# ISP_HIST register map
Vendor: Texas Instruments
Peripheral module from a debugger description file (folder omap36xx).
Registers are 32-bit, read-write, reset 0x0 unless marked. A register's access mark holds for its fields unless they carry their own. Offsets are as the file gives them; lines under a group give offsets from that group; [hi:lo] are bit positions; {n}, {i} and the like mark numbered series; 'fields as' and 'values as' point back to an identical list; <NAME> marks a mode.

## ISP_HIST
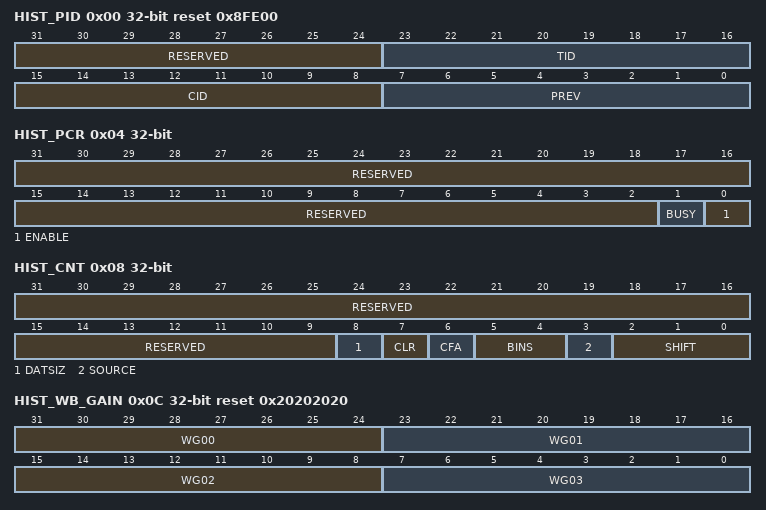
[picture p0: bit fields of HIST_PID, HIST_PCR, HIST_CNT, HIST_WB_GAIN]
0x00 HIST_PID ro reset 0x8FE00 (reset mask 0xFFFFFF00) — PERIPHERAL ID REGISTER
  [31:24] RESERVED — Write 0s for future compatibility. Reads returns 0.
  [23:16] TID — Peripheral identification: HIST module
  [15:8] CID — Class identification: Camera ISP
  [7:0] PREV — Peripheral revision number
0x04 HIST_PCR — PERIPHERAL CONTROL REGISTER
  [31:2] RESERVED — Write 0s for future compatibility.Reads returns 0.
  [1] BUSY — HIST module busy.
    0=Module is not busy; 1=Module is busy
  [0] ENABLE — HIST module enable.
    0=Disable module; 1=Enable module
0x08 HIST_CNT — HISTOGRAM CONTROL REGISTER
  [31:9] RESERVED — Write 0s for future compatibility.Reads returns 0.
  [8] DATSIZ — Input data width
    0=The pixels are coded on more than 8 bits; 1=The pixels are coded on 8 bits
  [7] CLR — Clear histogram data after read.
    0=Don't clear the data after read; 1=Clear the data after read
  [6] CFA — CFA pattern.
    0=Bayer pattern
  [5:4] BINS — Number of bins.
    0=32 bins, REGIONS 0, 1, 2 and 3 are active; 1=64 bins, REGIONS 0, 1, 2 and 3 are active; 2=128 bins, REGIONS 0 and 1 are active; 3=256 bins, REGION 0 is active
  [3] SOURCE — Input source.
    0=The input data comes from the CCDC module; 1=The input data comes from memory
  [2:0] SHIFT — Shift value. The pixel data is right shifted before the binning operation. The shift value can vary from 0 to 7.
0x0C HIST_WB_GAIN reset 0x20202020 — HISTOGRAM WHITE BALANCE GAIN REGISTER
  [31-8n:24-8n] WG{n:02} (n=0..3) — White balance gain {n:02}. The gain value is unsigned and in 3Q5 representation. It varies from 0 to 7.96875.
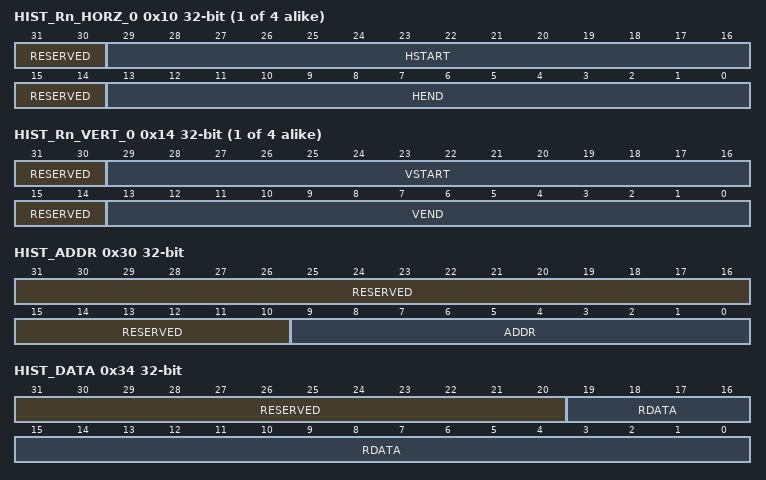
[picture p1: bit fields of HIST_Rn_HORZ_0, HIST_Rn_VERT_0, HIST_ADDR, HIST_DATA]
{0x10+8i} HIST_Rn_HORZ_{i} (i=0..3) — REGION n HORIZONTAL REGISTER
  [31:30] RESERVED — Write 0s for future compatibility.Reads returns 0.
  [29:16] HSTART — Horizontal start position for REGION n. From 0 to 16383.
  [15:14] RESERVED — Write 0s for future compatibility.Reads returns 0.
  [13:0] HEND — Horizontal end position for REGION n. From 0 to 16383.
{0x14+8i} HIST_Rn_VERT_{i} (i=0..3) — REGION n VERTICAL REGISTER
  [31:30] RESERVED — Write 0s for future compatibility.Reads returns 0.
  [29:16] VSTART — Vertical start position for REGION n. From 0 to 16383.
  [15:14] RESERVED — Write 0s for future compatibility.Reads returns 0.
  [13:0] VEND — Vertical end position for REGION n. From 0 to 16383.
0x30 HIST_ADDR — HISTOGRAM ADDRESS REGISTER
  [31:10] RESERVED — Write 0s for future compatibility.Reads returns 0.
  [9:0] ADDR — Histogram memory address. The histogram memory has 1024 entries. Each entry is coded on 20 bits.
0x34 HIST_DATA (reset mask 0xFFF00000)
  [31:20] RESERVED — Write 0s for future compatibility.Reads returns 0.
  [19:0] RDATA — Histogram data. The histogram memory has 1024 entries. Each entry is coded on 20 bits.
0x38 HIST_RADD — ADDRESS REGISTER This register is used only if the HIST module input data comes from memory instead of the CCDC module.
  [31:0] RADD — 32-bit address. The 5 LSBs are ignored: the starting address should be aligned on a 32-byte boundary.
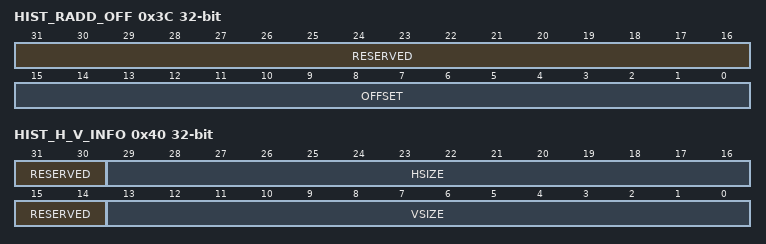
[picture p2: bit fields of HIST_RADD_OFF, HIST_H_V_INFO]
0x3C HIST_RADD_OFF — ADDRESS OFFSET REGISTER This register is used only if the HIST module input data comes from memory instead of the CCDC module.
  [31:16] RESERVED — Write 0s for future compatibility.Reads returns 0.
  [15:0] OFFSET — Offset value. The 5 LSBs are ignored: the offset must be a multiple of 32-bytes.
0x40 HIST_H_V_INFO — IMAGE SIZE REGISTER This register is used only if the HIST module input data comes from memory instead of the CCDC module.
  [31:30] RESERVED — Write 0s for future compatibility.Reads returns 0.
  [29:16] HSIZE — Horizontal size
  [15:14] RESERVED — Write 0s for future compatibility.Reads returns 0.
  [13:0] VSIZE — Vertical size
